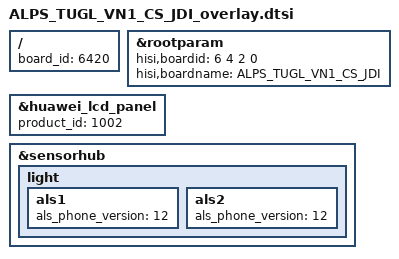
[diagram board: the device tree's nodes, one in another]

/**
 * Copyright (C) 2014 Hisilicon Ltd.
 *
 *  This program is free software; you can redistribute it and/or modify
 *  it under the terms of the GNU General Public License version 2 as
 *  publishhed by the Free Software Foundation.
 */

/include/ "ALPS_TUGL_V4_CS_CD23_overlay.dtsi"

/ {
	board_id = <6420>;
};

&rootparam {
    hisi,boardid = <6 4 2 0>;
    hisi,boardname = "ALPS_TUGL_VN1_CS_JDI";
};

	&huawei_lcd_panel {
		product_id = <1002>;
	};
	&sensorhub{
		light{
			als1{
				als_phone_version = <12>;
			};
			als2{
				als_phone_version = <12>;
			};
		};
	};
